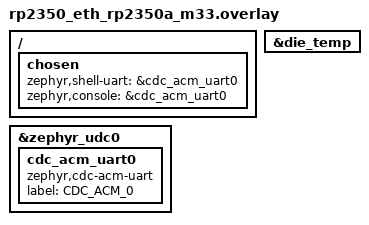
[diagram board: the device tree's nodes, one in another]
/*
 * SPDX-License-Identifier: Apache-2.0
 *
 * Copyright (c) 2024 TOKITA Hiroshi <tokita.hiroshi@fujitsu.com>
 */

/ {
	chosen {
		zephyr,shell-uart = &cdc_acm_uart0;
		zephyr,console = &cdc_acm_uart0;
	};
};

&zephyr_udc0 {
	cdc_acm_uart0: cdc_acm_uart0 {
		compatible = "zephyr,cdc-acm-uart";
		label = "CDC_ACM_0";
	};
};

&die_temp {
	status = "okay";
};
